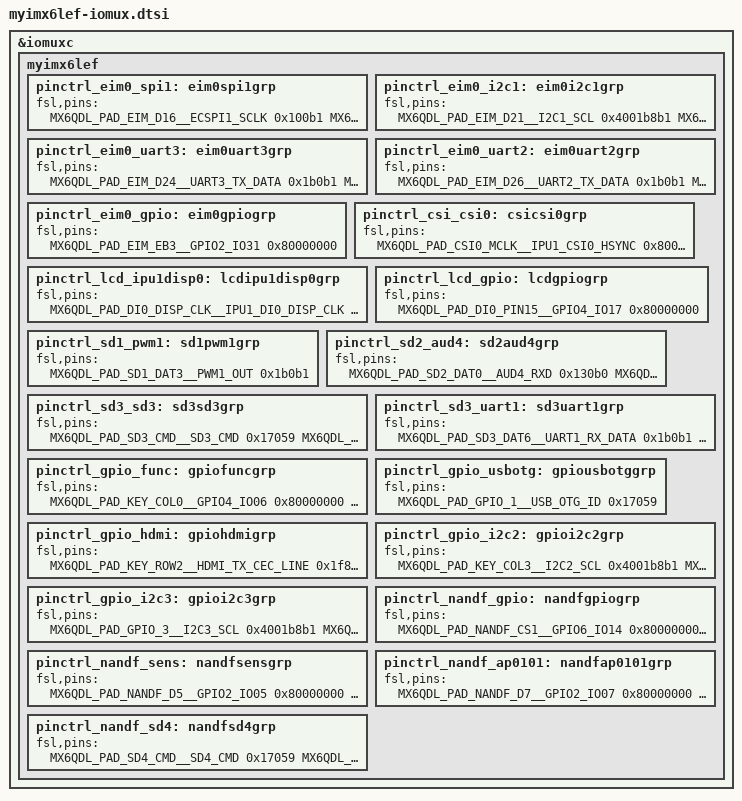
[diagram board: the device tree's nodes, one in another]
/*
 * MYZR Technology Co.,Ltd
 * http://www.myzr.com.cn
 * Tang Bin <tangb@myzr.com.cn>
 */

&iomuxc {
	myimx6lef {
		pinctrl_eim0_spi1: eim0spi1grp {
			fsl,pins = <
				MX6QDL_PAD_EIM_D16__ECSPI1_SCLK		0x100b1
				MX6QDL_PAD_EIM_D17__ECSPI1_MISO		0x100b1
				MX6QDL_PAD_EIM_D18__ECSPI1_MOSI		0x100b1
				/* SPI1 CS1 */
				MX6QDL_PAD_EIM_D19__GPIO3_IO19		0x80000000
			>;
		};
		pinctrl_eim0_i2c1: eim0i2c1grp {
			fsl,pins = <
				MX6QDL_PAD_EIM_D21__I2C1_SCL		0x4001b8b1
				MX6QDL_PAD_EIM_D28__I2C1_SDA		0x4001b8b1
			>;
		};
		pinctrl_eim0_uart3: eim0uart3grp {
			fsl,pins = <
				MX6QDL_PAD_EIM_D24__UART3_TX_DATA	0x1b0b1
				MX6QDL_PAD_EIM_D25__UART3_RX_DATA	0x1b0b1
			>;
		};
		pinctrl_eim0_uart2: eim0uart2grp {
			fsl,pins = <
				MX6QDL_PAD_EIM_D26__UART2_TX_DATA	0x1b0b1
				MX6QDL_PAD_EIM_D27__UART2_RX_DATA	0x1b0b1
			>;
		};
		pinctrl_eim0_gpio: eim0gpiogrp {
			fsl,pins = <
				/* GPS DET */
				MX6QDL_PAD_EIM_EB3__GPIO2_IO31		0x80000000
			>;
		};
		
		
		pinctrl_csi_csi0: csicsi0grp {
			fsl,pins = <
				MX6QDL_PAD_CSI0_MCLK__IPU1_CSI0_HSYNC    	0x80000000
				MX6QDL_PAD_CSI0_PIXCLK__IPU1_CSI0_PIXCLK 	0x80000000
				MX6QDL_PAD_CSI0_VSYNC__IPU1_CSI0_VSYNC   	0x80000000
				
				MX6QDL_PAD_CSI0_DAT4__IPU1_CSI0_DATA04   	0x80000000
				MX6QDL_PAD_CSI0_DAT5__IPU1_CSI0_DATA05   	0x80000000
				MX6QDL_PAD_CSI0_DAT6__IPU1_CSI0_DATA06   	0x80000000
				MX6QDL_PAD_CSI0_DAT7__IPU1_CSI0_DATA07   	0x80000000
				MX6QDL_PAD_CSI0_DAT8__IPU1_CSI0_DATA08   	0x80000000
				MX6QDL_PAD_CSI0_DAT9__IPU1_CSI0_DATA09   	0x80000000
				MX6QDL_PAD_CSI0_DAT10__IPU1_CSI0_DATA10  	0x80000000
				MX6QDL_PAD_CSI0_DAT11__IPU1_CSI0_DATA11  	0x80000000
				MX6QDL_PAD_CSI0_DAT12__IPU1_CSI0_DATA12  	0x80000000
				MX6QDL_PAD_CSI0_DAT13__IPU1_CSI0_DATA13  	0x80000000
				MX6QDL_PAD_CSI0_DAT14__IPU1_CSI0_DATA14  	0x80000000
				MX6QDL_PAD_CSI0_DAT15__IPU1_CSI0_DATA15  	0x80000000
				MX6QDL_PAD_CSI0_DAT16__IPU1_CSI0_DATA16  	0x80000000
				MX6QDL_PAD_CSI0_DAT17__IPU1_CSI0_DATA17  	0x80000000
				MX6QDL_PAD_CSI0_DAT18__IPU1_CSI0_DATA18  	0x80000000
				MX6QDL_PAD_CSI0_DAT19__IPU1_CSI0_DATA19  	0x80000000
			>;
		};
		
		
		pinctrl_lcd_ipu1disp0: lcdipu1disp0grp {
			fsl,pins = <
				MX6QDL_PAD_DI0_DISP_CLK__IPU1_DI0_DISP_CLK 0x10
				MX6QDL_PAD_DI0_PIN2__IPU1_DI0_PIN02        0x10
				MX6QDL_PAD_DI0_PIN3__IPU1_DI0_PIN03        0x10
				MX6QDL_PAD_DI0_PIN4__IPU1_DI0_PIN04        0x80000000
				/* MX6QDL_PAD_DI0_PIN15__IPU1_DI0_PIN15       0x10 */
				MX6QDL_PAD_DISP0_DAT0__IPU1_DISP0_DATA00   0x10
				MX6QDL_PAD_DISP0_DAT1__IPU1_DISP0_DATA01   0x10
				MX6QDL_PAD_DISP0_DAT2__IPU1_DISP0_DATA02   0x10
				MX6QDL_PAD_DISP0_DAT3__IPU1_DISP0_DATA03   0x10
				MX6QDL_PAD_DISP0_DAT4__IPU1_DISP0_DATA04   0x10
				MX6QDL_PAD_DISP0_DAT5__IPU1_DISP0_DATA05   0x10
				MX6QDL_PAD_DISP0_DAT6__IPU1_DISP0_DATA06   0x10
				MX6QDL_PAD_DISP0_DAT7__IPU1_DISP0_DATA07   0x10
				MX6QDL_PAD_DISP0_DAT8__IPU1_DISP0_DATA08   0x10
				MX6QDL_PAD_DISP0_DAT9__IPU1_DISP0_DATA09   0x10
				MX6QDL_PAD_DISP0_DAT10__IPU1_DISP0_DATA10  0x10
				MX6QDL_PAD_DISP0_DAT11__IPU1_DISP0_DATA11  0x10
				MX6QDL_PAD_DISP0_DAT12__IPU1_DISP0_DATA12  0x10
				MX6QDL_PAD_DISP0_DAT13__IPU1_DISP0_DATA13  0x10
				MX6QDL_PAD_DISP0_DAT14__IPU1_DISP0_DATA14  0x10
				MX6QDL_PAD_DISP0_DAT15__IPU1_DISP0_DATA15  0x10
				MX6QDL_PAD_DISP0_DAT16__IPU1_DISP0_DATA16  0x10
				MX6QDL_PAD_DISP0_DAT17__IPU1_DISP0_DATA17  0x10
				MX6QDL_PAD_DISP0_DAT18__IPU1_DISP0_DATA18  0x10
				MX6QDL_PAD_DISP0_DAT19__IPU1_DISP0_DATA19  0x10
				MX6QDL_PAD_DISP0_DAT20__IPU1_DISP0_DATA20  0x10
				MX6QDL_PAD_DISP0_DAT21__IPU1_DISP0_DATA21  0x10
				MX6QDL_PAD_DISP0_DAT22__IPU1_DISP0_DATA22  0x10
				MX6QDL_PAD_DISP0_DAT23__IPU1_DISP0_DATA23  0x10
			>;
		};
		pinctrl_lcd_gpio: lcdgpiogrp {
			fsl,pins = <
				/* HP DET */
				MX6QDL_PAD_DI0_PIN15__GPIO4_IO17			0x80000000
			>;
		};
		
		
		pinctrl_sd1_pwm1: sd1pwm1grp {
			fsl,pins = <
				MX6QDL_PAD_SD1_DAT3__PWM1_OUT		0x1b0b1
			>;
		};
		
		
		pinctrl_sd2_aud4: sd2aud4grp {
			fsl,pins = <
				MX6QDL_PAD_SD2_DAT0__AUD4_RXD		0x130b0
				MX6QDL_PAD_SD2_DAT1__AUD4_TXFS		0x130b0
				MX6QDL_PAD_SD2_DAT2__AUD4_TXD		0x110b0
				MX6QDL_PAD_SD2_DAT3__AUD4_TXC		0x130b0
			>;
		};
		
		
		pinctrl_sd3_sd3: sd3sd3grp {
			fsl,pins = <
				MX6QDL_PAD_SD3_CMD__SD3_CMD			0x17059
				MX6QDL_PAD_SD3_CLK__SD3_CLK			0x10059
				MX6QDL_PAD_SD3_DAT0__SD3_DATA0		0x17059
				MX6QDL_PAD_SD3_DAT1__SD3_DATA1		0x17059
				MX6QDL_PAD_SD3_DAT2__SD3_DATA2		0x17059
				MX6QDL_PAD_SD3_DAT3__SD3_DATA3		0x17059
				MX6QDL_PAD_SD3_DAT4__GPIO7_IO01		0x80000000
				MX6QDL_PAD_SD3_RST__GPIO7_IO08		0x80000000
			>;
		};
		pinctrl_sd3_uart1: sd3uart1grp {
			fsl,pins = <
				MX6QDL_PAD_SD3_DAT6__UART1_RX_DATA	0x1b0b1
				MX6QDL_PAD_SD3_DAT7__UART1_TX_DATA	0x1b0b1
			>;
		};
		
		
		pinctrl_gpio_func: gpiofuncgrp {
			fsl,pins = <
				/* IR_IN */
				MX6QDL_PAD_KEY_COL0__GPIO4_IO06		0x80000000
				MX6QDL_PAD_GPIO_0__CCM_CLKO1		0x80000000
				/* ISP STANDBY */
				/* MX6QDL_PAD_GPIO_4__GPIO1_IO04		0x80000000 */
				/* A12 TFT IO */
				MX6QDL_PAD_GPIO_8__GPIO1_IO08		0x80000000
				/* GPIO7_11 */
				MX6QDL_PAD_GPIO_16__GPIO7_IO11		0x80000000
				/* PSHOLD_PMU */
				MX6QDL_PAD_GPIO_17__GPIO7_IO12		0x80000000
				/* INT_PMU */
				MX6QDL_PAD_GPIO_18__GPIO7_IO13		0x80000000
				/* GPIO4_5 */
				MX6QDL_PAD_GPIO_19__GPIO4_IO05		0x80000000
			>;
		};
		pinctrl_gpio_usbotg: gpiousbotggrp {
			fsl,pins = <
				MX6QDL_PAD_GPIO_1__USB_OTG_ID		0x17059
			>;
		};
		pinctrl_gpio_hdmi: gpiohdmigrp {
			fsl,pins = <
				MX6QDL_PAD_KEY_ROW2__HDMI_TX_CEC_LINE	0x1f8b0
			>;
		};
		pinctrl_gpio_i2c2: gpioi2c2grp {
			fsl,pins = <
				MX6QDL_PAD_KEY_COL3__I2C2_SCL		0x4001b8b1
				MX6QDL_PAD_KEY_ROW3__I2C2_SDA		0x4001b8b1
			>;
		};
		pinctrl_gpio_i2c3: gpioi2c3grp {
			fsl,pins = <
				MX6QDL_PAD_GPIO_3__I2C3_SCL			0x4001b8b1
				MX6QDL_PAD_GPIO_6__I2C3_SDA			0x4001b8b1
			>;
		};
		
		
		pinctrl_nandf_gpio: nandfgpiogrp {
			fsl,pins = <
				MX6QDL_PAD_NANDF_CS1__GPIO6_IO14	0x80000000
				MX6QDL_PAD_NANDF_CS2__GPIO6_IO15	0x80000000
				MX6QDL_PAD_NANDF_CS3__GPIO6_IO16	0x80000000
				MX6QDL_PAD_NANDF_D0__GPIO2_IO00		0x80000000
				MX6QDL_PAD_NANDF_D1__GPIO2_IO01		0x80000000
				MX6QDL_PAD_NANDF_D2__GPIO2_IO02		0x80000000
				MX6QDL_PAD_NANDF_D3__GPIO2_IO03		0x80000000
				MX6QDL_PAD_NANDF_D4__GPIO2_IO04		0x80000000
			>;
		};
		pinctrl_nandf_sens: nandfsensgrp {
			fsl,pins = <
				MX6QDL_PAD_NANDF_D5__GPIO2_IO05		0x80000000
				MX6QDL_PAD_NANDF_D6__GPIO2_IO06		0x80000000
			>;
		};
		pinctrl_nandf_ap0101: nandfap0101grp {
			fsl,pins = <
				MX6QDL_PAD_NANDF_D7__GPIO2_IO07		0x80000000
				MX6QDL_PAD_GPIO_4__GPIO1_IO04		0x80000000 
			>;
		};
		pinctrl_nandf_sd4: nandfsd4grp {
			fsl,pins = <
				MX6QDL_PAD_SD4_CMD__SD4_CMD			0x17059
				MX6QDL_PAD_SD4_CLK__SD4_CLK			0x10059
				MX6QDL_PAD_SD4_DAT0__SD4_DATA0		0x17059
				MX6QDL_PAD_SD4_DAT1__SD4_DATA1		0x17059
				MX6QDL_PAD_SD4_DAT2__SD4_DATA2		0x17059
				MX6QDL_PAD_SD4_DAT3__SD4_DATA3		0x17059
				MX6QDL_PAD_SD4_DAT4__SD4_DATA4		0x17059
				MX6QDL_PAD_SD4_DAT5__SD4_DATA5		0x17059
				MX6QDL_PAD_SD4_DAT6__SD4_DATA6		0x17059
				MX6QDL_PAD_SD4_DAT7__SD4_DATA7		0x17059
			>;
		};
	};
};
